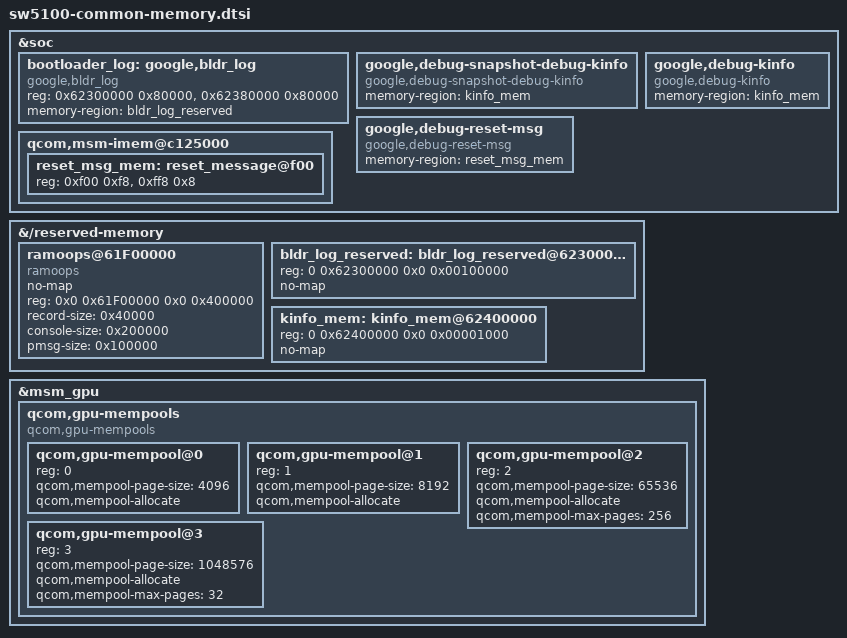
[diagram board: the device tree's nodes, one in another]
// SPDX-License-Identifier: GPL-2.0

&soc {
	bootloader_log: google,bldr_log {
		compatible = "google,bldr_log";
		reg = <0x62300000 0x80000>, <0x62380000 0x80000>;
		reg-names = "bl_log", "bl_old_log";
		memory-region = <&bldr_log_reserved>;
	};

	google,debug-snapshot-debug-kinfo {
		compatible = "google,debug-snapshot-debug-kinfo";
		memory-region = <&kinfo_mem>;
	};

	google,debug-kinfo {
		compatible = "google,debug-kinfo";
		memory-region = <&kinfo_mem>;
	};

	google,debug-reset-msg {
		compatible = "google,debug-reset-msg";
		memory-region = <&reset_msg_mem>;
	};

	qcom,msm-imem@c125000 {
		reset_msg_mem: reset_message@f00 {
			reg = <0xf00 0xf8>, <0xff8 0x8>;
		};
	};
};

&{/reserved-memory} {
	ramoops@61F00000 {
		no-map;
		compatible = "ramoops";
		reg = <0x0 0x61F00000 0x0 0x400000>;
		record-size = <0x40000>;
		console-size = <0x200000>;
		pmsg-size = <0x100000>;
	};

	bldr_log_reserved: bldr_log_reserved@62300000 {
		reg = <0 0x62300000 0x0 0x00100000>;
		no-map;
	};

	kinfo_mem: kinfo_mem@62400000 {
		reg = <0 0x62400000 0x0 0x00001000>;
		no-map;
	};
};

&msm_gpu {
	/* GPU Mempools */
	qcom,gpu-mempools {
		#address-cells = <1>;
		#size-cells = <0>;
		compatible = "qcom,gpu-mempools";

		/* 4K Page Pool configuration */
		qcom,gpu-mempool@0 {
			reg = <0>;
			qcom,mempool-page-size = <4096>;
			qcom,mempool-allocate;
		};
		/* 8K Page Pool configuration */
		qcom,gpu-mempool@1 {
			reg = <1>;
			qcom,mempool-page-size = <8192>;
			qcom,mempool-allocate;
		};
		/* 64K Page Pool configuration */
		qcom,gpu-mempool@2 {
			reg = <2>;
			qcom,mempool-page-size = <65536>;
			qcom,mempool-allocate;
			qcom,mempool-max-pages = <256>;
		};
		/* 1M Page Pool configuration */
		qcom,gpu-mempool@3 {
			reg = <3>;
			qcom,mempool-page-size = <1048576>;
			qcom,mempool-allocate;
			qcom,mempool-max-pages = <32>;
		};
	};
};
